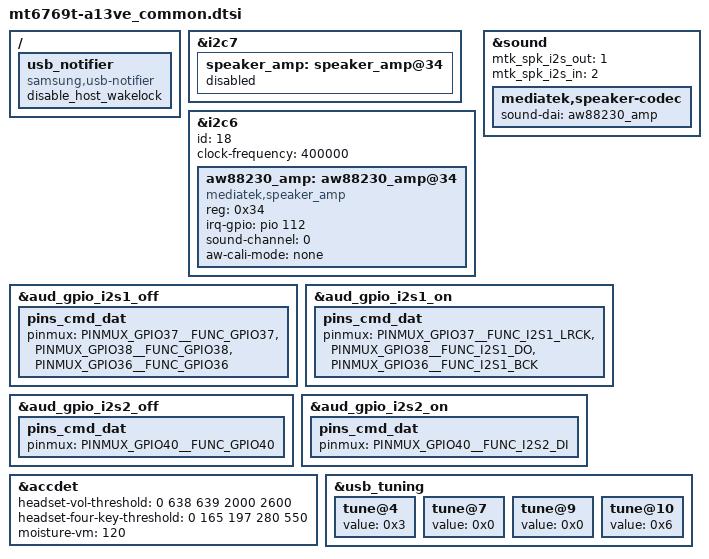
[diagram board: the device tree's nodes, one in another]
/* Generated by Samsung for MTK vendor board
 * If these files should be changed, then please make a sync with MTK
*/
#include "display_lcd_a13ve_common.dtsi"

/* Add Samsung configuration over here */
/ {
	fragment@model {
		target-path = "/";
		__overlay__ {
			usb_notifier {
				compatible = "samsung,usb-notifier";
				disable_host_wakelock;
			};
		};
	};
};

&i2c7 {
	speaker_amp: speaker_amp@34 {
		status = "disabled";
	};
};

&i2c6 {
	status = "okay";
	id = <18>;
	clock-frequency = <400000>;
	#address-cells = <1>;
	#size-cells = <0>;

	aw88230_amp: aw88230_amp@34 {
		compatible = "mediatek,speaker_amp";
		#sound-dai-cells = <0>;
		reg = <0x34>;
		irq-gpio = <&pio 112 0>;
		sound-channel = <0>;
		aw-cali-mode = "none";
		status = "okay";
	};
};

&sound {
	mtk_spk_i2s_out = <1>;
	mtk_spk_i2s_in = <2>;
	mediatek,speaker-codec {
		sound-dai = <&aw88230_amp>;
	};
};

/* I2S gpio configuration */
&aud_gpio_i2s1_off {
	pins_cmd_dat {
		pinmux = <PINMUX_GPIO37__FUNC_GPIO37>,
			 <PINMUX_GPIO38__FUNC_GPIO38>,
			 <PINMUX_GPIO36__FUNC_GPIO36>;
	};
};

&aud_gpio_i2s1_on {
	pins_cmd_dat {
		pinmux = <PINMUX_GPIO37__FUNC_I2S1_LRCK>,
			 <PINMUX_GPIO38__FUNC_I2S1_DO>,
			 <PINMUX_GPIO36__FUNC_I2S1_BCK>;
	};
};

&aud_gpio_i2s2_off {
	pins_cmd_dat {
		pinmux = <PINMUX_GPIO40__FUNC_GPIO40>;
	};
};

&aud_gpio_i2s2_on {
	pins_cmd_dat {
		pinmux = <PINMUX_GPIO40__FUNC_I2S2_DI>;
	};
};

&accdet {
	/*min_3pole--max_3pole--min_4pole--max_4pole--vol_bias*/
	headset-vol-threshold = <0 638 639 2000 2600>;
	/*0--MD_MAX--VOICE_MAX--UP_MAX--DW_MAX*/
	headset-four-key-threshold = <0 165 197 280 550>;

	/* moisture SW mode config start, use external resister or not.
	 */
	moisture-vm = <120>;
	/* moisture SW mode config end */
};

&usb_tuning {
	/* term_vref_sel */
	tune@4 {
		value = <0x3>;
	};
	/* hstx_srctrl */
	tune@7 {
		value = <0x0>;
	};
	/* sqth */
	tune@9 {
		value = <0x0>;
	};
	/* discth */
	tune@10 {
		value = <0x6>;
	};
};
